# CH32H417 register map
Vendor: WCH Ltd.; File version: 1.3
Registers are 32-bit, read-write, reset 0x0 unless marked. A register's access mark holds for its fields unless they carry their own. Offsets are from the block's base; [hi:lo] are bit positions; 'fields as' and 'values as' point back to an identical list.

## SERDES — Serial-parallel interconversion controller and transceiver
Base 0x40027C00
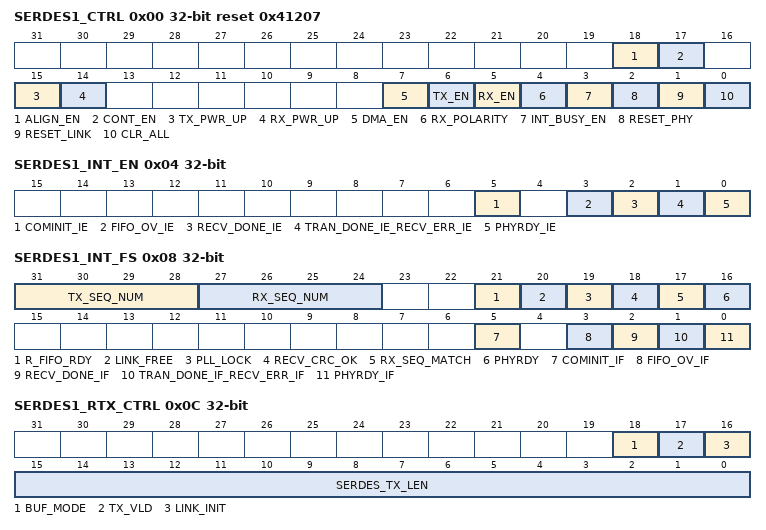
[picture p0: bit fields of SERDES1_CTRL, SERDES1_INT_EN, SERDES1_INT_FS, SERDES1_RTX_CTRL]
0x00 SERDES1_CTRL reset 0x41207 — SERDESx Control Register
  [18] ALIGN_EN — A ALIGN signal is inserted at the time of transmission, and it is highly effective to solve the frequency offset
  [17] CONT_EN — Replace the SYNC at idle with CONT and scrambling data to reduce EMI
  [15] TX_PWR_UP — Power-on enable bit of transmit module
  [14] RX_PWR_UP — Receiver module power-up enable bit
  [7] DMA_EN — DMA enables
  [6] TX_EN — Send Enable
  [5] RX_EN — Receiver Enable
  [4] RX_POLARITY — RXN/RXP signal exchange
  [3] INT_BUSY_EN — The SERDES transmission is complete, and the interruption flag is not cleared
  [2] RESET_PHY — SERDES Physical Layer Software Reset Control Bits
  [1] RESET_LINK — SERDES Link Layer Software Reset Control Bits
  [0] CLR_ALL — Clear the SERDES interrupt flag and FIFO
0x04 SERDES1_INT_EN — SERDESx interrupt enable register
  [5] COMINIT_IE — COMIT RECEIVE INTERRUPT ENABLES
  [3] FIFO_OV_IE — FIFO overflow interrupt enabled
  [2] RECV_DONE_IE — Receive Completion Interrupt Enables
  [1] TRAN_DONE_IE_RECV_ERR_IE — Transmission Mode: Interrupt Enabled for Transmission Completion; Receive Mode: Receive CRC Error Interrupt Enabled
  [0] PHYRDY_IE — PHYS-LAYER READY INTERRUPT ENABLES
0x08 SERDES1_INT_FS access per field — SERDESx Interrupt Flag/Status Register
  [31:28] TX_SEQ_NUM ro — LINK_INIT automatically clears when it is valid
  [27:24] RX_SEQ_NUM ro — In the receive mode, the received COMINT is automatically cleared
  [21] R_FIFO_RDY ro — SERDES receives FIFO data readiness status
  [20] LINK_FREE ro — The SERDES link layer sends the idle status bits
  [19] PLL_LOCK ro — The PLL locks the status bit
  [18] RECV_CRC_OK ro — The receive dataframe checks the status bit, detects it after RECV_DONE interrupt, and updates it after the packet is received
  [17] RX_SEQ_MATCH ro — Receive SEQ_NUM match status bits
  [16] PHYRDY ro — The physical layer READY status bit
  [5] COMINIT_IF rw — COMIT receives the interrupt flag
  [3] FIFO_OV_IF rw — FIFO overflows the interrupt flag
  [2] RECV_DONE_IF rw — Receive the Interrupt Completion flag
  [1] TRAN_DONE_IF_RECV_ERR_IF rw — Sending Mode: The signal of the interrupt is completed. Receive Mode: Receives the CRC error interrupt flag.
  [0] PHYRDY_IF rw — The physical layer READY interrupt flag
0x0C SERDES1_RTX_CTRL — SERDESx Transceiver Controller
  [18] BUF_MODE — Double-buffered control bit
  [17] TX_VLD — The sent packet is valid, zeroed by the software, and the bit is returned and synchronized with the PHY_CLK
  [16] LINK_INIT — This bit is 1 and sends a LINK initialization packet
  [15:0] SERDES_TX_LEN — Number of data bytes sent, the lower 2 bits are fixed at 0 (4-byte aligned)
0x10 SERDES1_RX_LEN0 ro — SERDESx Receive Length 0 Register
  [15:0] SERDES_RX_LEN0 — The packet length of the last received data, with the lowest 2 digits fixed at 0
0x14 SERDES1_DATA0 — SERDESx Data 0 Buffer Register
  [31:0] SERDES_DATA0 — SERDES data buffer 0
0x18 SERDES1_DMA0 — Start address register
  [31:0] SERDES_DMA0 — Buffer 0 start address, in receive mode, the software needs to align the lower 4 fixed bits 0 (16 bytes), and in send mode, it does not need to align 16 bytes
0x1C SERDES1_RX_LEN1 ro — SERDESx Receive Length 1 Register
  [15:0] SERDES_RX_LEN1 — The packet length of the last received data, with the lowest 2 digits fixed at 1
0x20 SERDES1_DATA1 — SERDESx Data 1 Buffer Register
  [31:0] SERDES_DATA1 — SERDES data buffer 1
0x24 SERDES1_DMA1 — Start address register
  [31:0] SERDES_DMA1 — Buffer 0 start address, in receive mode, the software needs to align the lower 4 fixed bits 0 (16 bytes), and in send mode, it does not need to align 16 bytes
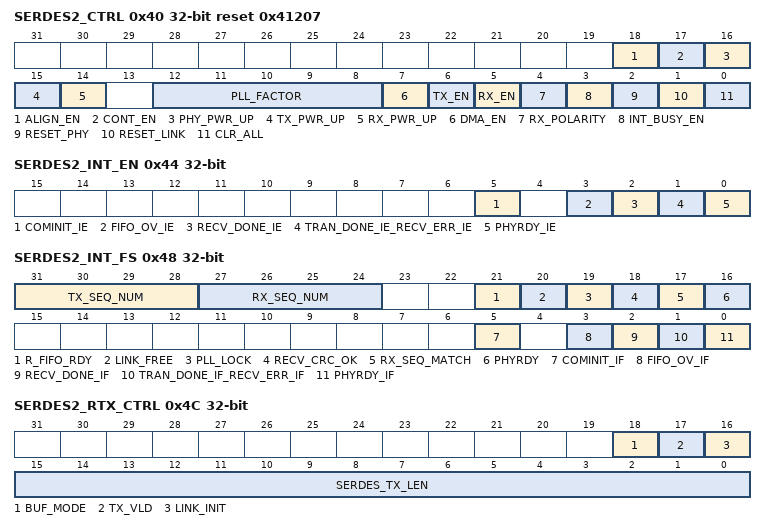
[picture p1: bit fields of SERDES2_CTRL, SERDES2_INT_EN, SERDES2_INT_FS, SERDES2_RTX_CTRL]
0x40 SERDES2_CTRL reset 0x41207 — SERDESx Control Register
  [18] ALIGN_EN — A ALIGN signal is inserted at the time of transmission, and it is highly effective to solve the frequency offset
  [17] CONT_EN — Replace the SYNC at idle with CONT and scrambling data to reduce EMI
  [16] PHY_PWR_UP — Enable bits on the physical layer
  [15] TX_PWR_UP — Power-on enable bit of transmit module
  [14] RX_PWR_UP — Receiver module power-up enable bit
  [12:8] PLL_FACTOR — PLL Clock Control Coefficient
  [7] DMA_EN — DMA enables
  [6] TX_EN — Send Enable
  [5] RX_EN — Receiver Enable
  [4] RX_POLARITY — RXN/RXP signal exchange
  [3] INT_BUSY_EN — The SERDES transmission is complete, and the interruption flag is not cleared
  [2] RESET_PHY — SERDES Physical Layer Software Reset Control Bits
  [1] RESET_LINK — SERDES Link Layer Software Reset Control Bits
  [0] CLR_ALL — Clear the SERDES interrupt flag and FIFO
0x44 SERDES2_INT_EN — SERDESx interrupt enable register
  fields as SERDES1_INT_EN
0x48 SERDES2_INT_FS access per field — SERDESx Interrupt Flag/Status Register
  fields as SERDES1_INT_FS
0x4C SERDES2_RTX_CTRL — SERDESx Transceiver Controller
  fields as SERDES1_RTX_CTRL
0x50 SERDES2_RX_LEN0 ro — SERDESx Receive Length 0 Register
  fields as SERDES1_RX_LEN0
0x54 SERDES2_DATA0 — SERDESx Data 0 Buffer Register
  [31:0] SERDES_DATA0 — SERDES data buffer 0
0x58 SERDES2_DMA0 — Start address register
  fields as SERDES1_DMA0
0x5C SERDES2_RX_LEN1 ro — SERDESx Receive Length 1 Register
  fields as SERDES1_RX_LEN1
0x60 SERDES2_DATA1 — SERDESx Data 1 Buffer Register
  [31:0] SERDES_DATA1 — SERDES data buffer 1
0x64 SERDES2_DMA1 — Start address register
  fields as SERDES1_DMA1
